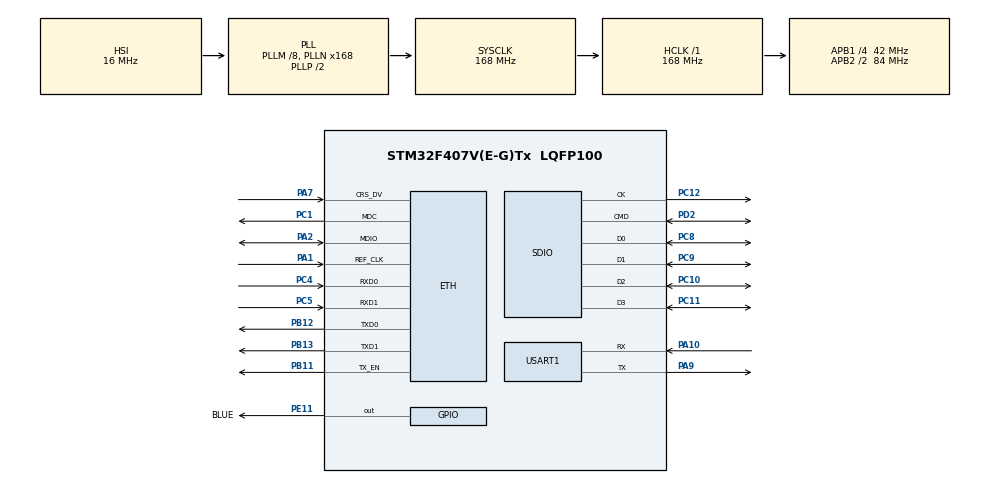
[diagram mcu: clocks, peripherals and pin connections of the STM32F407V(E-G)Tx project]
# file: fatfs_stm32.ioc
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Mcu.Family=STM32F4
FATFS._USE_FORWARD=1
Dma.SDIO_TX.1.MemInc=DMA_MINC_ENABLE
PH0-OSC_IN.Signal=RCC_OSC_IN
RCC.CortexFreq_Value=168000000
FATFS._USE_LFN=3
VP_FATFS_VS_SDIO.Mode=SDIO
PE11.GPIO_Label=BLUE
PC10.Signal=SDIO_D2
PC12.Signal=SDIO_CK
PE11.PinState=GPIO_PIN_SET
PC5.Mode=RMII
PB11.Signal=ETH_TX_EN
PB13.Signal=ETH_TXD1
Dma.SDIO_TX.1.PeriphBurst=DMA_PBURST_INC4
RCC.SYSCLKSource=RCC_SYSCLKSOURCE_PLLCLK
ProjectManager.StackSize=0x2000
Dma.SDIO_RX.0.Direction=DMA_PERIPH_TO_MEMORY
VP_FREERTOS_VS_CMSIS_V2.Mode=CMSIS_V2
LWIP.NETMASK_ADDRESS=255.255.255.000
Dma.SDIO_TX.1.Instance=DMA2_Stream6
Dma.SDIO_TX.1.PeriphInc=DMA_PINC_DISABLE
Dma.SDIO_TX.1.PeriphDataAlignment=DMA_PDATAALIGN_WORD
PE11.GPIO_PuPd=GPIO_NOPULL
RCC.HCLKFreq_Value=168000000
RCC.APB2TimFreq_Value=168000000
Dma.SDIO_TX.1.FIFOMode=DMA_FIFOMODE_ENABLE
RCC.AHBFreq_Value=168000000
PH0-OSC_IN.Mode=HSE-External-Oscillator
NVIC.ETH_IRQn=true\:5\:0\:false\:false\:true\:true\:false\:true
RCC.HSE_VALUE=25000000
NVIC.TIM8_TRG_COM_TIM14_IRQn=true\:0\:0\:false\:false\:true\:false\:false\:true
Dma.SDIO_TX.1.MemBurst=DMA_MBURST_INC4
PA14.Mode=Serial_Wire
PC9.Mode=SD_4_bits_Wide_bus
Dma.SDIO_TX.1.Direction=DMA_MEMORY_TO_PERIPH
VP_SYS_VS_tim14.Mode=TIM14
Dma.SDIO_RX.0.MemDataAlignment=DMA_MDATAALIGN_WORD
FATFS._USE_LABEL=1
PH1-OSC_OUT.Mode=HSE-External-Oscillator
Mcu.Package=LQFP100
PB12.Mode=RMII
NVIC.TimeBase=TIM8_TRG_COM_TIM14_IRQn
NVIC.TimeBaseIP=TIM14
PA10.Signal=USART1_RX
PC11.Mode=SD_4_bits_Wide_bus
Dma.SDIO_TX.1.FIFOThreshold=DMA_FIFO_THRESHOLD_FULL
Dma.SDIO_TX.1.Priority=DMA_PRIORITY_LOW
FATFS._FS_MINIMIZE=0
RCC.APB2CLKDivider=RCC_HCLK_DIV2
Dma.Request1=SDIO_TX
RCC.APB1TimFreq_Value=84000000
PC5.Signal=ETH_RXD1
Dma.SDIO_RX.0.MemBurst=DMA_MBURST_INC4
PB13.Mode=RMII
Dma.SDIO_RX.0.Instance=DMA2_Stream3
Dma.Request0=SDIO_RX
PC4.Mode=RMII
Dma.SDIO_RX.0.FIFOMode=DMA_FIFOMODE_ENABLE
LWIP.IP_ADDRESS=192.168.111.020
Dma.SDIO_RX.0.Mode=DMA_PFCTRL
Dma.SDIO_RX.0.Priority=DMA_PRIORITY_LOW
FREERTOS.Tasks01=defaultTask,24,1024,StartDefaultTask,Default,NULL,Dynamic,NULL,NULL
PA7.Mode=RMII
ETH.PHY_User_Name=LAN8720
PA10.Mode=Asynchronous
PC11.Signal=SDIO_D3
PC8.Signal=SDIO_D0
Dma.SDIO_RX.0.PeriphInc=DMA_PINC_DISABLE
PC4.Signal=ETH_RXD0
PC10.Mode=SD_4_bits_Wide_bus
LWIP.LWIP_DHCP=0
RCC.APB1CLKDivider=RCC_HCLK_DIV4
ETH.PhyAddress=0
NVIC.SDIO_IRQn=true\:5\:0\:true\:false\:true\:true\:true\:true
VP_LWIP_VS_Enabled.Mode=Enabled
LWIP.GATEWAY_ADDRESS=192.168.111.001
PA13.Signal=SYS_JTMS-SWDIO
PA9.Mode=Asynchronous
Dma.SDIO_TX.1.MemDataAlignment=DMA_MDATAALIGN_WORD
Dma.SDIO_RX.0.MemInc=DMA_MINC_ENABLE
ETH.PHY_Name_RMII=userPHY
PB11.Mode=RMII
Dma.SDIO_RX.0.FIFOThreshold=DMA_FIFO_THRESHOLD_FULL
ProjectManager.TargetToolchain=STM32CubeIDE
FATFS._CODE_PAGE=850
PA9.Signal=USART1_TX
NVIC.DMA2_Stream3_IRQn=true\:6\:0\:true\:false\:true\:true\:false\:true
NVIC.DMA2_Stream6_IRQn=true\:6\:0\:true\:false\:true\:true\:false\:true
PE11.Signal=GPIO_Output
RCC.LSE_VALUE=32768
PA1.Signal=ETH_REF_CLK
Dma.SDIO_RX.0.PeriphDataAlignment=DMA_PDATAALIGN_WORD
PD2.Mode=SD_4_bits_Wide_bus
PC12.Mode=SD_4_bits_Wide_bus
FATFS._USE_EXPAND=1
board=custom
RCC.VCOOutputFreq_Value=336000000
ETH.PHY_SR=31
LWIP.LWIP_TFTP=1
RCC.APB2Freq_Value=84000000
PA1.Mode=RMII
PH1-OSC_OUT.Signal=RCC_OSC_OUT
Dma.SDIO_TX.1.Mode=DMA_PFCTRL
FATFS._USE_FIND=1
PA13.Mode=Serial_Wire
Mcu.Name=STM32F407V(E-G)Tx
PA2.Signal=ETH_MDIO
FATFS._USE_CHMOD=1
PC8.Mode=SD_4_bits_Wide_bus
RCC.48MHZClocksFreq_Value=48000000
RCC.SYSCLKFreq_VALUE=168000000
ETH.MediaInterface=ETH_MEDIA_INTERFACE_RMII
USART1.VirtualMode=VM_ASYNC
PA14.Signal=SYS_JTCK-SWCLK
ProjectManager.HeapSize=0x2000
LWIP.Version=v2.1.2_Cube
RCC.HSI_VALUE=16000000
RCC.PLLQ=7
NVIC.PriorityGroup=NVIC_PRIORITYGROUP_4
RCC.PLLM=8
SDIO.HardwareFlowControl=SDIO_HARDWARE_FLOW_CONTROL_DISABLE
RCC.PLLN=168
Dma.SDIO_RX.0.PeriphBurst=DMA_PBURST_INC4
PA2.Mode=RMII
PC9.Signal=SDIO_D1
PD2.Signal=SDIO_CMD
RCC.APB1Freq_Value=42000000
PC1.Signal=ETH_MDC
PB12.Signal=ETH_TXD0
PC1.Mode=RMII
PA7.Signal=ETH_CRS_DV

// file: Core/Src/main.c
/* USER CODE BEGIN Header */
/**
  ******************************************************************************
  * @file           : main.c
  * @brief          : Main program body
  ******************************************************************************
  * @attention
  *
  * <h2><center>&copy; Copyright (c) 2021 STMicroelectronics.
  * All rights reserved.</center></h2>
  *
  * This software component is licensed by ST under Ultimate Liberty license
  * SLA0044, the "License"; You may not use this file except in compliance with
  * the License. You may obtain a copy of the License at:
  *                             www.st.com/SLA0044
  *
  ******************************************************************************
  */
/* USER CODE END Header */
#include "main.h"
#include "cmsis_os.h"
#include "dma.h"
#include "fatfs.h"
#include "lwip.h"
#include "sdio.h"
#include "usart.h"
#include "gpio.h"

/* USER CODE BEGIN Includes */
#include "stdio.h"
/* USER CODE END Includes */

void SystemClock_Config(void);
void MX_FREERTOS_Init(void);

int main(void)
{

  /* MCU Configuration--------------------------------------------------------*/

  /* Reset of all peripherals, Initializes the Flash interface and the Systick. */
  HAL_Init();

  /* Configure the system clock */
  SystemClock_Config();

  /* Initialize all configured peripherals */
  MX_GPIO_Init();
  MX_DMA_Init();
  MX_SDIO_SD_Init();
  MX_USART1_UART_Init();
  MX_FATFS_Init();
  /* USER CODE BEGIN 2 */
  printf("\r\nFatFS DMA Freertos example. \r\nFirmware compile date: %s %s\r\n", __DATE__, __TIME__);
  /* USER CODE END 2 */

  /* Init scheduler */
  osKernelInitialize();  /* Call init function for freertos objects (in freertos.c) */
  MX_FREERTOS_Init();
  /* Start scheduler */
  osKernelStart();

  /* We should never get here as control is now taken by the scheduler */
  /* Infinite loop */
  while (1)
  {

  }
}

void SystemClock_Config(void)
{
  RCC_OscInitTypeDef RCC_OscInitStruct = {0};
  RCC_ClkInitTypeDef RCC_ClkInitStruct = {0};

  /** Configure the main internal regulator output voltage
  */
  __HAL_RCC_PWR_CLK_ENABLE();
  __HAL_PWR_VOLTAGESCALING_CONFIG(PWR_REGULATOR_VOLTAGE_SCALE1);
  /** Initializes the RCC Oscillators according to the specified parameters
  * in the RCC_OscInitTypeDef structure.
  */
  RCC_OscInitStruct.OscillatorType = RCC_OSCILLATORTYPE_HSI;
  RCC_OscInitStruct.HSIState = RCC_HSI_ON;
  RCC_OscInitStruct.HSICalibrationValue = RCC_HSICALIBRATION_DEFAULT;
  RCC_OscInitStruct.PLL.PLLState = RCC_PLL_ON;
  RCC_OscInitStruct.PLL.PLLSource = RCC_PLLSOURCE_HSI;
  RCC_OscInitStruct.PLL.PLLM = 8;
  RCC_OscInitStruct.PLL.PLLN = 168;
  RCC_OscInitStruct.PLL.PLLP = RCC_PLLP_DIV2;
  RCC_OscInitStruct.PLL.PLLQ = 7;
  if (HAL_RCC_OscConfig(&RCC_OscInitStruct) != HAL_OK)
  {
    Error_Handler();
  }
  /** Initializes the CPU, AHB and APB buses clocks
  */
  RCC_ClkInitStruct.ClockType = RCC_CLOCKTYPE_HCLK|RCC_CLOCKTYPE_SYSCLK
                              |RCC_CLOCKTYPE_PCLK1|RCC_CLOCKTYPE_PCLK2;
  RCC_ClkInitStruct.SYSCLKSource = RCC_SYSCLKSOURCE_PLLCLK;
  RCC_ClkInitStruct.AHBCLKDivider = RCC_SYSCLK_DIV1;
  RCC_ClkInitStruct.APB1CLKDivider = RCC_HCLK_DIV4;
  RCC_ClkInitStruct.APB2CLKDivider = RCC_HCLK_DIV2;

  if (HAL_RCC_ClockConfig(&RCC_ClkInitStruct, FLASH_LATENCY_5) != HAL_OK)
  {
    Error_Handler();
  }
}

 /**
  * @brief  Period elapsed callback in non blocking mode
  * @note   This function is called  when TIM14 interrupt took place, inside
  * HAL_TIM_IRQHandler(). It makes a direct call to HAL_IncTick() to increment
  * a global variable "uwTick" used as application time base.
  * @param  htim : TIM handle
  * @retval None
  */
void HAL_TIM_PeriodElapsedCallback(TIM_HandleTypeDef *htim)
{
  if (htim->Instance == TIM14) {
    HAL_IncTick();
  }
}

void Error_Handler(void)
{
  /* USER CODE BEGIN Error_Handler_Debug */
  /* User can add his own implementation to report the HAL error return state */
  printf("something error\r\n");
  __disable_irq();
  while (1)
  {
  }
  /* USER CODE END Error_Handler_Debug */
}

/************************ (C) COPYRIGHT STMicroelectronics *****END OF FILE****/

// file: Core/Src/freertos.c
/* USER CODE BEGIN Header */
/**
  ******************************************************************************
  * File Name          : freertos.c
  * Description        : Code for freertos applications
  ******************************************************************************
  * @attention
  *
  * <h2><center>&copy; Copyright (c) 2021 STMicroelectronics.
  * All rights reserved.</center></h2>
  *
  * This software component is licensed by ST under Ultimate Liberty license
  * SLA0044, the "License"; You may not use this file except in compliance with
  * the License. You may obtain a copy of the License at:
  *                             www.st.com/SLA0044
  *
  ******************************************************************************
  */
/* USER CODE END Header */

#include "FreeRTOS.h"
#include "task.h"
#include "main.h"
#include "cmsis_os.h"

/* USER CODE BEGIN Includes */
#include "fatfs.h"
#include "stdio.h"
#include "tftpserverif.h"
/* USER CODE END Includes */

/* Definitions for defaultTask */
osThreadId_t defaultTaskHandle;
const osThreadAttr_t defaultTask_attributes = {
  .name = "defaultTask",
  .priority = (osPriority_t) osPriorityNormal,
  .stack_size = 1024 * 4
};

void StartDefaultTask(void *argument);

extern void MX_LWIP_Init(void);
void MX_FREERTOS_Init(void); /* (MISRA C 2004 rule 8.1) */

void MX_FREERTOS_Init(void) {

  /* Create the thread(s) */
  /* creation of defaultTask */
  defaultTaskHandle = osThreadNew(StartDefaultTask, NULL, &defaultTask_attributes);

}

void StartDefaultTask(void *argument)
{
  /* init code for LWIP */
  MX_LWIP_Init();
  /* USER CODE BEGIN StartDefaultTask */
//  uint32_t byteswritten;                /* File write counts */
//  uint32_t bytesread;                   /* File read counts */
//  uint8_t wtext[] = "This is STM32 working with FatFs_with_DMA_and_Freertos mode"; /* File write buffer */
//  uint8_t rtext[100];
//  char filename[] = "stm32_11111.txt";
//  /*##-1- Register the file system object to the FatFs module ##############*/
//  retSD = f_mount(&SDFatFS,"", 1);
//  if(retSD)
//  {
//    printf("mount error : %d \r\n",retSD);
//    Error_Handler();
//  }
//  else
//    printf("mount sucess!!! \r\n");
//  /*##-2- Create and Open new text file objects with write access ######*/
//  retSD = f_open(&SDFile, filename, FA_CREATE_ALWAYS | FA_WRITE);
//  if(retSD)
//    printf("open file error : %d\r\n",retSD);
//  else
//    printf("open file sucess!!! \r\n");
//  /*##-3- Write data to the text files ###############################*/
//  retSD = f_write(&SDFile, wtext, sizeof(wtext), (void *)&byteswritten);
//  if(retSD)
//    printf("write file error : %d\r\n",retSD);
//  else
//  {
//    printf("write file sucess!!! \r\n");
//    printf("write Data : %s\r\n",wtext);
//  }
//  /*##-4- Close the open text files ################################*/
//  retSD = f_close(&SDFile);
//  if(retSD)
//    printf("close error : %d\r\n",retSD);
//  else
//    printf("close sucess!!! \r\n");
//
//  /*##-5- Open the text files object with read access ##############*/
//  retSD = f_open(&SDFile, filename, FA_READ);
//  if(retSD)
//    printf("open file error : %d\r\n",retSD);
//  else
//    printf("open file sucess!!! \r\n");
//
//  /*##-6- Read data from the text files ##########################*/
//  retSD = f_read(&SDFile, rtext, sizeof(rtext), (UINT*)&bytesread);
//  if(retSD)
//    printf("read error!!! %d\r\n",retSD);
//  else
//  {
//    printf("read sucess!!! \r\n");
//    printf("read Data : %s\r\n",rtext);
//  }
//
//  /*##-7- Close the open text files ############################*/
//  retSD = f_close(&SDFile);
//  if(retSD)
//    printf("close error!!! %d\r\n",retSD);
//  else
//    printf("close sucess!!! \r\n");
//
//  /*##-8- Compare read data with the expected data ############*/
//  if(bytesread == byteswritten)
//  {
//    printf("FatFs is working well!!!\r\n");
//  }
  tftpserverif_init();
  /* Infinite loop */
  for(;;)
  {
    osDelay(1000);
    HAL_GPIO_TogglePin(BLUE_GPIO_Port, BLUE_Pin);
  }
  /* USER CODE END StartDefaultTask */
}

/************************ (C) COPYRIGHT STMicroelectronics *****END OF FILE****/
